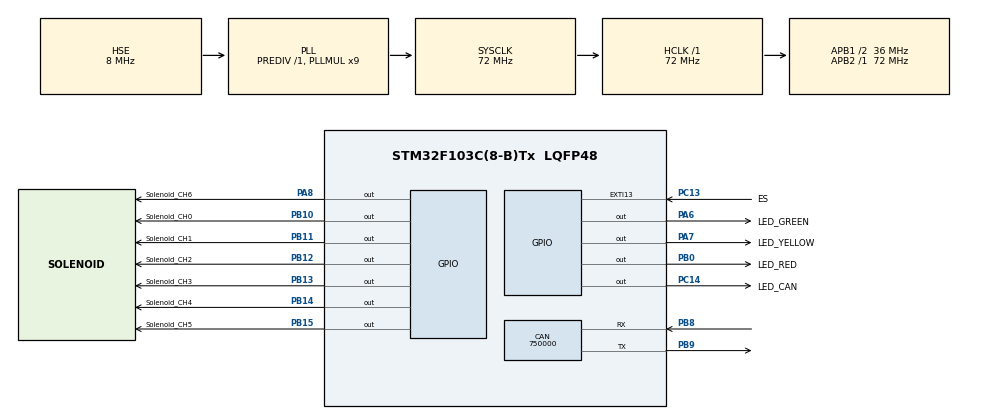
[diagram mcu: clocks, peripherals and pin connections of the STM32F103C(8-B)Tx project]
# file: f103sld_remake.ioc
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Mcu.Family=STM32F1
RCC.PLLSourceVirtual=RCC_PLLSOURCE_HSE
PD1-OSC_OUT.Mode=HSE-External-Oscillator
CAN.CalculateBaudRate=750000
PB14.GPIO_Label=Solenoid_CH4
PB11.GPIO_Label=Solenoid_CH1
PC13-TAMPER-RTC.Signal=GPXTI13
PA6.GPIO_Label=LED_GREEN
PB0.GPIO_Label=LED_RED
PD0-OSC_IN.Signal=RCC_OSC_IN
RCC.APB1CLKDivider=RCC_HCLK_DIV2
PC14-OSC32_IN.Signal=GPIO_Output
PB13.GPIO_Label=Solenoid_CH3
PB11.Signal=GPIO_Output
PB13.Signal=GPIO_Output
PB15.Signal=GPIO_Output
CAN.CalculateTimeBit=1333.33
RCC.SYSCLKSource=RCC_SYSCLKSOURCE_PLLCLK
ProjectManager.StackSize=0x400
PD1-OSC_OUT.Signal=RCC_OSC_OUT
PA13.Signal=SYS_JTMS-SWDIO
PA8.GPIO_Label=Solenoid_CH6
ProjectManager.TargetToolchain=STM32CubeIDE
PB10.GPIO_Label=Solenoid_CH0
RCC.HCLKFreq_Value=72000000
PB9.Mode=CAN_Activate
RCC.APB2TimFreq_Value=72000000
RCC.USBFreq_Value=72000000
RCC.AHBFreq_Value=72000000
RCC.PREFETCH_ENABLE=1
PD0-OSC_IN.Mode=HSE-External-Oscillator
PB10.Signal=GPIO_Output
NVIC.EXTI15_10_IRQn=true\:0\:0\:false\:false\:true\:true\:true
PB14.Signal=GPIO_Output
board=custom
PC13-TAMPER-RTC.GPIO_ModeDefaultEXTI=GPIO_MODE_IT_FALLING
PC13-TAMPER-RTC.GPIO_Label=ES
RCC.PLLMUL=RCC_PLL_MUL9
PB12.GPIO_Label=Solenoid_CH2
RCC.APB2Freq_Value=72000000
PB15.GPIO_Label=Solenoid_CH5
PA14.Mode=Serial_Wire
NVIC.USB_LP_CAN1_RX0_IRQn=true\:0\:0\:false\:false\:true\:true\:true
PA8.Signal=GPIO_Output
PA13.Mode=Serial_Wire
Mcu.Name=STM32F103C(8-B)Tx
CAN.CalculateTimeQuantum=444.44444444444446
RCC.SYSCLKFreq_VALUE=72000000
Mcu.Package=LQFP48
PB9.Signal=CAN_TX
PA6.Signal=GPIO_Output
PA7.GPIO_Label=LED_YELLOW
PA14.Signal=SYS_JTCK-SWCLK
ProjectManager.HeapSize=0x200
NVIC.PriorityGroup=NVIC_PRIORITYGROUP_4
PB8.Mode=CAN_Activate
RCC.APB1TimFreq_Value=72000000
PB8.Signal=CAN_RX
PC14-OSC32_IN.GPIO_Label=LED_CAN
RCC.APB1Freq_Value=36000000
PB0.Signal=GPIO_Output
PB12.Signal=GPIO_Output
PA7.Signal=GPIO_Output

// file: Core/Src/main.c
/* USER CODE BEGIN Header */
/**
 ******************************************************************************
 * @file           : main.cpp
 * @brief          : Main program body
 ******************************************************************************
 * @attention
 *
 * <h2><center>&copy; Copyright (c) 2019 STMicroelectronics.
 * All rights reserved.</center></h2>
 *
 * This software component is licensed by ST under BSD 3-Clause license,
 * the "License"; You may not use this file except in compliance with the
 * License. You may obtain a copy of the License at:
 *                        opensource.org/licenses/BSD-3-Clause
 *
 ******************************************************************************
 */
/* USER CODE END Header */
#include "main.h"

/* USER CODE BEGIN PTD */
CAN_RxHeaderTypeDef rx_header;
/* USER CODE END PTD */

CAN_HandleTypeDef hcan;

void SystemClock_Config(void);
static void MX_GPIO_Init(void);
static void MX_CAN_Init(void);

int main(void)
{

  /* MCU Configuration--------------------------------------------------------*/

  /* Reset of all peripherals, Initializes the Flash interface and the Systick. */
  HAL_Init();

  /* Configure the system clock */
  SystemClock_Config();

  /* Initialize all configured peripherals */
  MX_GPIO_Init();
  MX_CAN_Init();
  /* USER CODE BEGIN 2 */
  main_cpp();
  /* USER CODE END 2 */

  /* Infinite loop */
  while (1)
  {

  }
}

void SystemClock_Config(void)
{
  RCC_OscInitTypeDef RCC_OscInitStruct = {0};
  RCC_ClkInitTypeDef RCC_ClkInitStruct = {0};

  /** Initializes the RCC Oscillators according to the specified parameters
  * in the RCC_OscInitTypeDef structure.
  */
  RCC_OscInitStruct.OscillatorType = RCC_OSCILLATORTYPE_HSE;
  RCC_OscInitStruct.HSEState = RCC_HSE_ON;
  RCC_OscInitStruct.HSEPredivValue = RCC_HSE_PREDIV_DIV1;
  RCC_OscInitStruct.HSIState = RCC_HSI_ON;
  RCC_OscInitStruct.PLL.PLLState = RCC_PLL_ON;
  RCC_OscInitStruct.PLL.PLLSource = RCC_PLLSOURCE_HSE;
  RCC_OscInitStruct.PLL.PLLMUL = RCC_PLL_MUL9;
  if (HAL_RCC_OscConfig(&RCC_OscInitStruct) != HAL_OK)
  {
    Error_Handler();
  }
  /** Initializes the CPU, AHB and APB buses clocks
  */
  RCC_ClkInitStruct.ClockType = RCC_CLOCKTYPE_HCLK|RCC_CLOCKTYPE_SYSCLK
                              |RCC_CLOCKTYPE_PCLK1|RCC_CLOCKTYPE_PCLK2;
  RCC_ClkInitStruct.SYSCLKSource = RCC_SYSCLKSOURCE_PLLCLK;
  RCC_ClkInitStruct.AHBCLKDivider = RCC_SYSCLK_DIV1;
  RCC_ClkInitStruct.APB1CLKDivider = RCC_HCLK_DIV2;
  RCC_ClkInitStruct.APB2CLKDivider = RCC_HCLK_DIV1;

  if (HAL_RCC_ClockConfig(&RCC_ClkInitStruct, FLASH_LATENCY_2) != HAL_OK)
  {
    Error_Handler();
  }
}

static void MX_CAN_Init(void)
{

  /* USER CODE BEGIN CAN_Init 0 */
////
  /* USER CODE END CAN_Init 0 */

  /* USER CODE BEGIN CAN_Init 1 */
////
  /* USER CODE END CAN_Init 1 */
  hcan.Instance = CAN1;
  hcan.Init.Prescaler = 16;
  hcan.Init.Mode = CAN_MODE_NORMAL;
  hcan.Init.SyncJumpWidth = CAN_SJW_1TQ;
  hcan.Init.TimeSeg1 = CAN_BS1_1TQ;
  hcan.Init.TimeSeg2 = CAN_BS2_1TQ;
  hcan.Init.TimeTriggeredMode = DISABLE;
  hcan.Init.AutoBusOff = DISABLE;
  hcan.Init.AutoWakeUp = DISABLE;
  hcan.Init.AutoRetransmission = DISABLE;
  hcan.Init.ReceiveFifoLocked = DISABLE;
  hcan.Init.TransmitFifoPriority = DISABLE;
  if (HAL_CAN_Init(&hcan) != HAL_OK)
  {
    Error_Handler();
  }
  /* USER CODE BEGIN CAN_Init 2 */
////
  /* USER CODE END CAN_Init 2 */

}

static void MX_GPIO_Init(void)
{
  GPIO_InitTypeDef GPIO_InitStruct = {0};

  /* GPIO Ports Clock Enable */
  __HAL_RCC_GPIOC_CLK_ENABLE();
  __HAL_RCC_GPIOD_CLK_ENABLE();
  __HAL_RCC_GPIOA_CLK_ENABLE();
  __HAL_RCC_GPIOB_CLK_ENABLE();

  /*Configure GPIO pin Output Level */
  HAL_GPIO_WritePin(LED_CAN_GPIO_Port, LED_CAN_Pin, GPIO_PIN_RESET);

  /*Configure GPIO pin Output Level */
  HAL_GPIO_WritePin(GPIOA, LED_GREEN_Pin|LED_YELLOW_Pin|Solenoid_CH6_Pin, GPIO_PIN_RESET);

  /*Configure GPIO pin Output Level */
  HAL_GPIO_WritePin(GPIOB, LED_RED_Pin|Solenoid_CH0_Pin|Solenoid_CH1_Pin|Solenoid_CH2_Pin
                          |Solenoid_CH3_Pin|Solenoid_CH4_Pin|Solenoid_CH5_Pin, GPIO_PIN_RESET);

  /*Configure GPIO pin : ES_Pin */
  GPIO_InitStruct.Pin = ES_Pin;
  GPIO_InitStruct.Mode = GPIO_MODE_IT_FALLING;
  GPIO_InitStruct.Pull = GPIO_NOPULL;
  HAL_GPIO_Init(ES_GPIO_Port, &GPIO_InitStruct);

  /*Configure GPIO pin : LED_CAN_Pin */
  GPIO_InitStruct.Pin = LED_CAN_Pin;
  GPIO_InitStruct.Mode = GPIO_MODE_OUTPUT_PP;
  GPIO_InitStruct.Pull = GPIO_NOPULL;
  GPIO_InitStruct.Speed = GPIO_SPEED_FREQ_LOW;
  HAL_GPIO_Init(LED_CAN_GPIO_Port, &GPIO_InitStruct);

  /*Configure GPIO pins : LED_GREEN_Pin LED_YELLOW_Pin Solenoid_CH6_Pin */
  GPIO_InitStruct.Pin = LED_GREEN_Pin|LED_YELLOW_Pin|Solenoid_CH6_Pin;
  GPIO_InitStruct.Mode = GPIO_MODE_OUTPUT_PP;
  GPIO_InitStruct.Pull = GPIO_NOPULL;
  GPIO_InitStruct.Speed = GPIO_SPEED_FREQ_LOW;
  HAL_GPIO_Init(GPIOA, &GPIO_InitStruct);

  /*Configure GPIO pins : LED_RED_Pin Solenoid_CH0_Pin Solenoid_CH1_Pin Solenoid_CH2_Pin
                           Solenoid_CH3_Pin Solenoid_CH4_Pin Solenoid_CH5_Pin */
  GPIO_InitStruct.Pin = LED_RED_Pin|Solenoid_CH0_Pin|Solenoid_CH1_Pin|Solenoid_CH2_Pin
                          |Solenoid_CH3_Pin|Solenoid_CH4_Pin|Solenoid_CH5_Pin;
  GPIO_InitStruct.Mode = GPIO_MODE_OUTPUT_PP;
  GPIO_InitStruct.Pull = GPIO_NOPULL;
  GPIO_InitStruct.Speed = GPIO_SPEED_FREQ_LOW;
  HAL_GPIO_Init(GPIOB, &GPIO_InitStruct);

  /* EXTI interrupt init*/
  HAL_NVIC_SetPriority(EXTI15_10_IRQn, 0, 0);
  HAL_NVIC_EnableIRQ(EXTI15_10_IRQn);

}

void Error_Handler(void)
{
}

/************************ (C) COPYRIGHT STMicroelectronics *****END OF FILE****/
